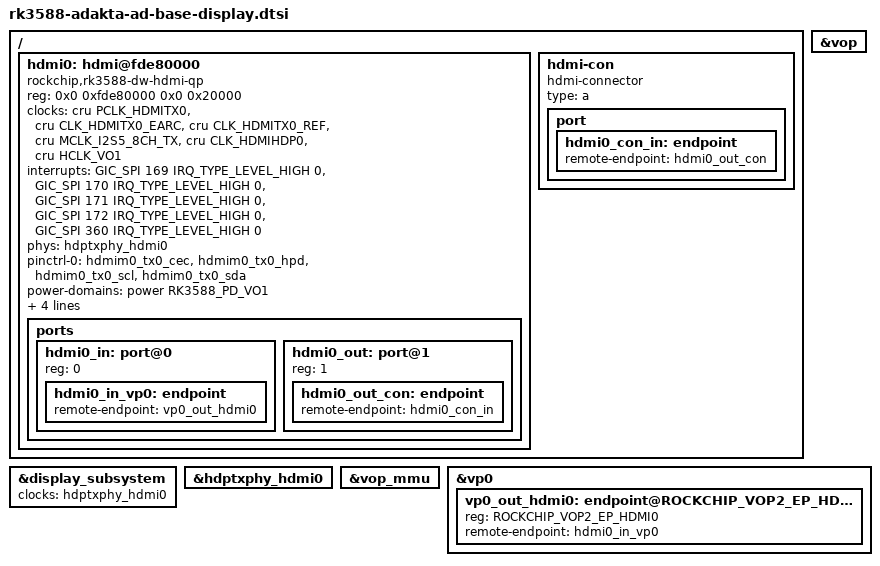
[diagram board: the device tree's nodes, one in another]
// SPDX-License-Identifier: (GPL-2.0+ OR MIT)
/*
 * Copyright (c) 2024 Adakta, Ltd.
 *
 */

/ {
	/* TODO: WIP no upstream patches */
	hdmi0: hdmi@fde80000 {
		compatible = "rockchip,rk3588-dw-hdmi-qp";
		reg = <0x0 0xfde80000 0x0 0x20000>;
		clocks = <&cru PCLK_HDMITX0>,
			 <&cru CLK_HDMITX0_EARC>,
			 <&cru CLK_HDMITX0_REF>,
			 <&cru MCLK_I2S5_8CH_TX>,
			 <&cru CLK_HDMIHDP0>,
			 <&cru HCLK_VO1>;
		clock-names = "pclk", "earc", "ref", "aud", "hdp", "hclk_vo1";
		interrupts = <GIC_SPI 169 IRQ_TYPE_LEVEL_HIGH 0>,
			     <GIC_SPI 170 IRQ_TYPE_LEVEL_HIGH 0>,
			     <GIC_SPI 171 IRQ_TYPE_LEVEL_HIGH 0>,
			     <GIC_SPI 172 IRQ_TYPE_LEVEL_HIGH 0>,
			     <GIC_SPI 360 IRQ_TYPE_LEVEL_HIGH 0>;
		interrupt-names = "avp", "cec", "earc", "main", "hpd";
		phys = <&hdptxphy_hdmi0>;
		pinctrl-names = "default";
		pinctrl-0 = <&hdmim0_tx0_cec &hdmim0_tx0_hpd
			     &hdmim0_tx0_scl &hdmim0_tx0_sda>;
		power-domains = <&power RK3588_PD_VO1>;
		resets = <&cru SRST_HDMITX0_REF>, <&cru SRST_HDMIHDP0>;
		reset-names = "ref", "hdp";
		rockchip,grf = <&sys_grf>;
		rockchip,vo-grf = <&vo1_grf>;
		status = "disabled";

		ports {
			#address-cells = <1>;
			#size-cells = <0>;

			hdmi0_in: port@0 {
				reg = <0>;
			};

			hdmi0_out: port@1 {
				reg = <1>;
			};
		};
	};

	hdmi-con {
		compatible = "hdmi-connector";
		type = "a";

		port {
			hdmi0_con_in: endpoint {
				remote-endpoint = <&hdmi0_out_con>;
			};
		};
	};
};

&display_subsystem {
	clocks = <&hdptxphy_hdmi0>;
	clock-names = "hdmi0_phy_pll";
};

&hdptxphy_hdmi0 {
	status = "okay";
};

&hdmi0 {
	status = "okay";
};

&hdmi0_in {
	hdmi0_in_vp0: endpoint {
		remote-endpoint = <&vp0_out_hdmi0>;
	};
};

&hdmi0_out {
	hdmi0_out_con: endpoint {
		remote-endpoint = <&hdmi0_con_in>;
	};
};

&vop {
	status = "okay";
};

&vop_mmu {
	status = "okay";
};

&vp0 {
	vp0_out_hdmi0: endpoint@ROCKCHIP_VOP2_EP_HDMI0 {
		reg = <ROCKCHIP_VOP2_EP_HDMI0>;
		remote-endpoint = <&hdmi0_in_vp0>;
	};
};
